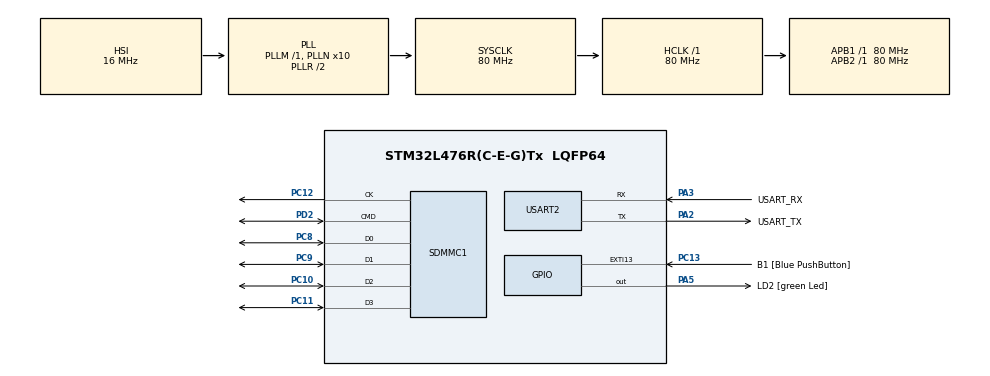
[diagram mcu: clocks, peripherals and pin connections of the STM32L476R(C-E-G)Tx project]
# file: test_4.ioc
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Dma.Request0=SDMMC1_RX
Dma.Request1=SDMMC1_TX
Dma.SDMMC1_RX.0.Direction=DMA_PERIPH_TO_MEMORY
Dma.SDMMC1_RX.0.Instance=DMA2_Channel4
Dma.SDMMC1_RX.0.MemDataAlignment=DMA_MDATAALIGN_WORD
Dma.SDMMC1_RX.0.MemInc=DMA_MINC_ENABLE
Dma.SDMMC1_RX.0.Mode=DMA_NORMAL
Dma.SDMMC1_RX.0.PeriphDataAlignment=DMA_PDATAALIGN_WORD
Dma.SDMMC1_RX.0.PeriphInc=DMA_PINC_DISABLE
Dma.SDMMC1_RX.0.Priority=DMA_PRIORITY_LOW
Dma.SDMMC1_TX.1.Direction=DMA_MEMORY_TO_PERIPH
Dma.SDMMC1_TX.1.Instance=DMA2_Channel5
Dma.SDMMC1_TX.1.MemDataAlignment=DMA_MDATAALIGN_WORD
Dma.SDMMC1_TX.1.MemInc=DMA_MINC_ENABLE
Dma.SDMMC1_TX.1.Mode=DMA_NORMAL
Dma.SDMMC1_TX.1.PeriphDataAlignment=DMA_PDATAALIGN_WORD
Dma.SDMMC1_TX.1.PeriphInc=DMA_PINC_DISABLE
Dma.SDMMC1_TX.1.Priority=DMA_PRIORITY_LOW
FATFS.USE_DMA_CODE_SD=1
Mcu.Family=STM32L4
Mcu.Name=STM32L476R(C-E-G)Tx
Mcu.Package=LQFP64
NVIC.DMA2_Channel4_IRQn=true\:0\:0\:false\:false\:true\:false\:true
NVIC.DMA2_Channel5_IRQn=true\:0\:0\:false\:false\:true\:false\:true
NVIC.PriorityGroup=NVIC_PRIORITYGROUP_4
NVIC.SDMMC1_IRQn=true\:0\:0\:false\:false\:true\:true\:true
PA13\ (JTMS-SWDIO).GPIO_Label=TMS
PA13\ (JTMS-SWDIO).Mode=Serial_Wire
PA13\ (JTMS-SWDIO).Signal=SYS_JTMS-SWDIO
PA14\ (JTCK-SWCLK).GPIO_Label=TCK
PA14\ (JTCK-SWCLK).Mode=Serial_Wire
PA14\ (JTCK-SWCLK).Signal=SYS_JTCK-SWCLK
PA2.GPIO_Label=USART_TX
PA2.GPIO_Mode=GPIO_MODE_AF_PP
PA2.GPIO_PuPd=GPIO_NOPULL
PA2.GPIO_Speed=GPIO_SPEED_FREQ_VERY_HIGH
PA2.Mode=Asynchronous
PA2.Signal=USART2_TX
PA3.GPIO_Label=USART_RX
PA3.GPIO_Mode=GPIO_MODE_AF_PP
PA3.GPIO_PuPd=GPIO_NOPULL
PA3.GPIO_Speed=GPIO_SPEED_FREQ_VERY_HIGH
PA3.Mode=Asynchronous
PA3.Signal=USART2_RX
PA5.GPIO_Label=LD2 [green Led]
PA5.GPIO_ModeDefaultOutputPP=GPIO_MODE_OUTPUT_PP
PA5.GPIO_PuPd=GPIO_NOPULL
PA5.GPIO_Speed=GPIO_SPEED_FREQ_LOW
PA5.Signal=GPIO_Output
PB3\ (JTDO-TRACESWO).GPIO_Label=SWO
PB3\ (JTDO-TRACESWO).Signal=SYS_JTDO-SWO
PC10.Mode=SD_4_bits_Wide_bus
PC10.Signal=SDMMC1_D2
PC11.Mode=SD_4_bits_Wide_bus
PC11.Signal=SDMMC1_D3
PC12.Mode=SD_4_bits_Wide_bus
PC12.Signal=SDMMC1_CK
PC13.GPIO_Label=B1 [Blue PushButton]
PC13.GPIO_ModeDefaultEXTI=GPIO_MODE_IT_FALLING
PC13.GPIO_PuPd=GPIO_NOPULL
PC13.Signal=GPXTI13
PC14-OSC32_IN\ (PC14).Mode=LSE-External-Oscillator
PC14-OSC32_IN\ (PC14).Signal=RCC_OSC32_IN
PC15-OSC32_OUT\ (PC15).Mode=LSE-External-Oscillator
PC15-OSC32_OUT\ (PC15).Signal=RCC_OSC32_OUT
PC8.Mode=SD_4_bits_Wide_bus
PC8.Signal=SDMMC1_D0
PC9.Mode=SD_4_bits_Wide_bus
PC9.Signal=SDMMC1_D1
PD2.Mode=SD_4_bits_Wide_bus
PD2.Signal=SDMMC1_CMD
PH0-OSC_IN\ (PH0).Signal=RCC_OSC_IN
PH1-OSC_OUT\ (PH1).Signal=RCC_OSC_OUT
ProjectManager.HeapSize=0x400
ProjectManager.StackSize=0x800
ProjectManager.TargetToolchain=STM32CubeIDE
RCC.ADCFreq_Value=64000000
RCC.AHBFreq_Value=80000000
RCC.APB1Freq_Value=80000000
RCC.APB1TimFreq_Value=80000000
RCC.APB2Freq_Value=80000000
RCC.APB2TimFreq_Value=80000000
RCC.CortexFreq_Value=80000000
RCC.HCLKFreq_Value=80000000
RCC.HSE_VALUE=8000000
RCC.HSI_VALUE=16000000
RCC.MSI_VALUE=4000000
RCC.PLLN=10
RCC.PLLSAI1Q=RCC_PLLQ_DIV4
RCC.PLLSourceVirtual=RCC_PLLSOURCE_HSI
RCC.PREFETCH_ENABLE=1
RCC.SYSCLKFreq_VALUE=80000000
RCC.SYSCLKSource=RCC_SYSCLKSOURCE_PLLCLK
RCC.USBFreq_Value=32000000
RCC.VCOOutputFreq_Value=160000000
USART2.VirtualMode-Asynchronous=VM_ASYNC
VP_FATFS_VS_SDIO.Mode=SDIO
board=NUCLEO-L476RG

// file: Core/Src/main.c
/* USER CODE BEGIN Header */
/**
  ******************************************************************************
  * @file           : main.c
  * @brief          : Main program body
  ******************************************************************************
  * @attention
  *
  * <h2><center>&copy; Copyright (c) 2022 STMicroelectronics.
  * All rights reserved.</center></h2>
  *
  * This software component is licensed by ST under BSD 3-Clause license,
  * the "License"; You may not use this file except in compliance with the
  * License. You may obtain a copy of the License at:
  *                        opensource.org/licenses/BSD-3-Clause
  *
  ******************************************************************************
  */
/* USER CODE END Header */
#include "main.h"
#include "dma.h"
#include "fatfs.h"
#include "sdmmc.h"
#include "usart.h"
#include "gpio.h"

void SystemClock_Config(void);

/* USER CODE BEGIN 0 */
void delay(int time)
{
    int i;
    for (i = 0; i < time * 4000; i++) {}
}
/* USER CODE END 0 */

int main(void)
{
  /* USER CODE BEGIN 1 */
	//RCC_APB2PeriphClockCmd(RCC_APB2Periph_GPIOA, ENABLE);
  /* USER CODE END 1 */

  /* MCU Configuration--------------------------------------------------------*/

  /* Reset of all peripherals, Initializes the Flash interface and the Systick. */
  HAL_Init();

  /* Configure the system clock */
  SystemClock_Config();

  /* Initialize all configured peripherals */
  MX_GPIO_Init();
  MX_DMA_Init();
  MX_USART2_UART_Init();
  MX_SDMMC1_SD_Init();
  MX_FATFS_Init();
  /* USER CODE BEGIN 2 */
  uint16_t heh = 0;
  /* USER CODE END 2 */

  /* Infinite loop */
  /* USER CODE BEGIN WHILE */
  while (1)
  {
	  //HAL_GPIO_TogglePin(LD2_GPIO_Port,LD2_Pin);
	 //HAL_GPIO_TogglePin(LD2_GPIO_Port, LD2_Pin);

	  delay(1000);
	  heh++;
	  HAL_GPIO_TogglePin(LD2_GPIO_Port,LD2_Pin);

	  //delay(1000);

	  //HAL_Delay(1000);

    /* USER CODE END WHILE */

  }
}

void SystemClock_Config(void)
{
  RCC_OscInitTypeDef RCC_OscInitStruct = {0};
  RCC_ClkInitTypeDef RCC_ClkInitStruct = {0};
  RCC_PeriphCLKInitTypeDef PeriphClkInit = {0};

  /** Initializes the RCC Oscillators according to the specified parameters
  * in the RCC_OscInitTypeDef structure.
  */
  RCC_OscInitStruct.OscillatorType = RCC_OSCILLATORTYPE_HSI;
  RCC_OscInitStruct.HSIState = RCC_HSI_ON;
  RCC_OscInitStruct.HSICalibrationValue = RCC_HSICALIBRATION_DEFAULT;
  RCC_OscInitStruct.PLL.PLLState = RCC_PLL_ON;
  RCC_OscInitStruct.PLL.PLLSource = RCC_PLLSOURCE_HSI;
  RCC_OscInitStruct.PLL.PLLM = 1;
  RCC_OscInitStruct.PLL.PLLN = 10;
  RCC_OscInitStruct.PLL.PLLP = RCC_PLLP_DIV7;
  RCC_OscInitStruct.PLL.PLLQ = RCC_PLLQ_DIV2;
  RCC_OscInitStruct.PLL.PLLR = RCC_PLLR_DIV2;
  if (HAL_RCC_OscConfig(&RCC_OscInitStruct) != HAL_OK)
  {
    Error_Handler();
  }
  /** Initializes the CPU, AHB and APB buses clocks
  */
  RCC_ClkInitStruct.ClockType = RCC_CLOCKTYPE_HCLK|RCC_CLOCKTYPE_SYSCLK
                              |RCC_CLOCKTYPE_PCLK1|RCC_CLOCKTYPE_PCLK2;
  RCC_ClkInitStruct.SYSCLKSource = RCC_SYSCLKSOURCE_PLLCLK;
  RCC_ClkInitStruct.AHBCLKDivider = RCC_SYSCLK_DIV1;
  RCC_ClkInitStruct.APB1CLKDivider = RCC_HCLK_DIV1;
  RCC_ClkInitStruct.APB2CLKDivider = RCC_HCLK_DIV1;

  if (HAL_RCC_ClockConfig(&RCC_ClkInitStruct, FLASH_LATENCY_4) != HAL_OK)
  {
    Error_Handler();
  }
  PeriphClkInit.PeriphClockSelection = RCC_PERIPHCLK_USART2|RCC_PERIPHCLK_SDMMC1;
  PeriphClkInit.Usart2ClockSelection = RCC_USART2CLKSOURCE_PCLK1;
  PeriphClkInit.Sdmmc1ClockSelection = RCC_SDMMC1CLKSOURCE_PLLSAI1;
  PeriphClkInit.PLLSAI1.PLLSAI1Source = RCC_PLLSOURCE_HSI;
  PeriphClkInit.PLLSAI1.PLLSAI1M = 1;
  PeriphClkInit.PLLSAI1.PLLSAI1N = 8;
  PeriphClkInit.PLLSAI1.PLLSAI1P = RCC_PLLP_DIV7;
  PeriphClkInit.PLLSAI1.PLLSAI1Q = RCC_PLLQ_DIV4;
  PeriphClkInit.PLLSAI1.PLLSAI1R = RCC_PLLR_DIV2;
  PeriphClkInit.PLLSAI1.PLLSAI1ClockOut = RCC_PLLSAI1_48M2CLK;
  if (HAL_RCCEx_PeriphCLKConfig(&PeriphClkInit) != HAL_OK)
  {
    Error_Handler();
  }
  /** Configure the main internal regulator output voltage
  */
  if (HAL_PWREx_ControlVoltageScaling(PWR_REGULATOR_VOLTAGE_SCALE1) != HAL_OK)
  {
    Error_Handler();
  }
}

void Error_Handler(void)
{
}

/************************ (C) COPYRIGHT STMicroelectronics *****END OF FILE****/
